VERSION ""

NS_ :

BS_:

BU_: SunroofControlModule Panel_Sim

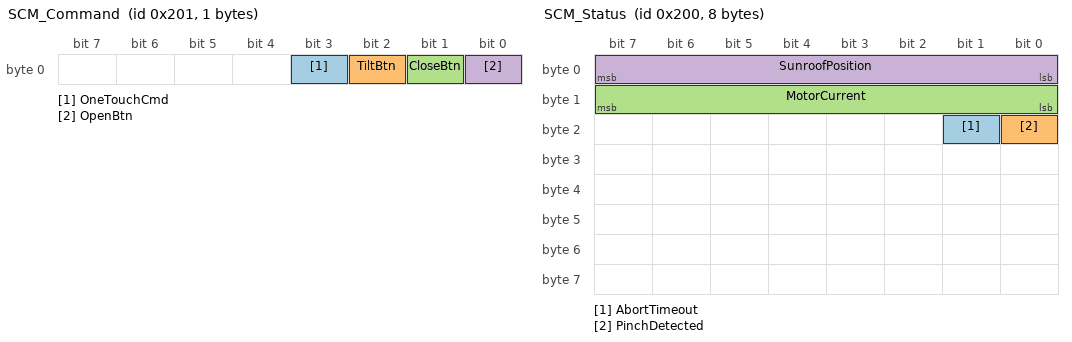
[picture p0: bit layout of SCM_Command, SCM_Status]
BO_ 513 SCM_Command: 1 Panel_Sim
 SG_ OneTouchCmd : 3|1@1+ (1,0) [0|1] "" SunroofControlModule
 SG_ TiltBtn : 2|1@1+ (1,0) [0|1] "" SunroofControlModule
 SG_ CloseBtn : 1|1@1+ (1,0) [0|1] "" SunroofControlModule
 SG_ OpenBtn : 0|1@1+ (1,0) [0|1] "" SunroofControlModule

BO_ 512 SCM_Status: 8 SunroofControlModule
 SG_ AbortTimeout : 17|1@1+ (1,0) [0|1] "" Panel_Sim
 SG_ PinchDetected : 16|1@1+ (1,0) [0|1] "" Panel_Sim
 SG_ MotorCurrent : 8|8@1+ (0.1,0) [0|20] "A" Panel_Sim
 SG_ SunroofPosition : 0|8@1+ (1,0) [0|100] "%" Panel_Sim

CM_ BO_ 513 "Command frame from Panel_Sim to SunroofControlModule.";
CM_ SG_ 513 OpenBtn "1 = open command.";
CM_ SG_ 513 CloseBtn "1 = close command.";
CM_ SG_ 513 TiltBtn "1 = tilt command.";
CM_ SG_ 513 OneTouchCmd "1 = one-touch-close command.";

CM_ BO_ 512 "Status frame from SunroofControlModule to Panel_Sim.";
CM_ SG_ 512 SunroofPosition "0 = fully open, 100 = fully closed.";
CM_ SG_ 512 MotorCurrent "Motor current in amperes.";
CM_ SG_ 512 PinchDetected "1 = pinch/obstruction detected.";
CM_ SG_ 512 AbortTimeout "1 = one-touch-close timeout.";

BA_DEF_ "BusType" STRING ;
BA_ "BusType" "CAN";
